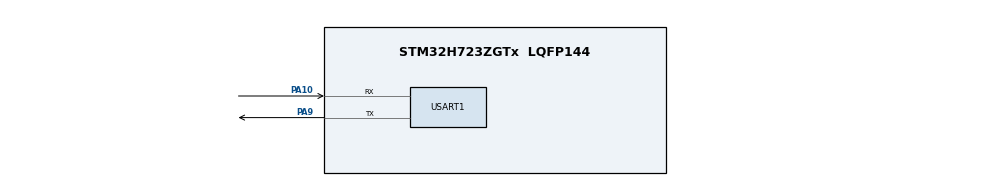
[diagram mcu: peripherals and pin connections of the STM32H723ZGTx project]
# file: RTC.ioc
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CORTEX_M7.default_mode_Activation=1
IWDG1.Prescaler=IWDG_PRESCALER_8
Mcu.Family=STM32H7
Mcu.Name=STM32H723ZGTx
Mcu.Package=LQFP144
NVIC.PriorityGroup=NVIC_PRIORITYGROUP_4
PA10.Mode=Asynchronous
PA10.Signal=USART1_RX
PA9.Mode=Asynchronous
PA9.Signal=USART1_TX
PC14-OSC32_IN.Mode=LSE-External-Oscillator
PC14-OSC32_IN.Signal=RCC_OSC32_IN
PC15-OSC32_OUT.Mode=LSE-External-Oscillator
PC15-OSC32_OUT.Signal=RCC_OSC32_OUT
PH0-OSC_IN.Mode=HSE-External-Oscillator
PH0-OSC_IN.Signal=RCC_OSC_IN
PH1-OSC_OUT.Mode=HSE-External-Oscillator
PH1-OSC_OUT.Signal=RCC_OSC_OUT
ProjectManager.HeapSize=0x200
ProjectManager.StackSize=0x400
ProjectManager.TargetToolchain=CMake
RCC.ADCFreq_Value=129000000
RCC.APB1Freq_Value=137500000
RCC.APB2Freq_Value=137500000
RCC.APB3Freq_Value=137500000
RCC.APB4Freq_Value=137500000
RCC.CortexFreq_Value=550000000
RCC.D1PPRE=RCC_APB3_DIV2
RCC.D2PPRE1=RCC_APB1_DIV2
RCC.D2PPRE2=RCC_APB2_DIV2
RCC.D3PPRE=RCC_APB4_DIV2
RCC.DIVM1=4
RCC.DIVN1=34
RCC.DIVP1=1
RCC.HCLKFreq_Value=275000000
RCC.HPRE=RCC_HCLK_DIV2
RCC.PLL2FRACN=0
RCC.PLL3FRACN=0
RCC.PLLFRACN=3072
RCC.SYSCLKFreq_VALUE=550000000
RCC.SYSCLKSource=RCC_SYSCLKSOURCE_PLLCLK
RCC.USBFreq_Value=275000000
USART1.VirtualMode-Asynchronous=VM_ASYNC
VP_IWDG1_VS_IWDG.Mode=IWDG_Activate
VP_MEMORYMAP_VS_MEMORYMAP.Mode=CurAppReg
VP_RTC_VS_RTC_Activate.Mode=RTC_Enabled
VP_RTC_VS_RTC_Calendar.Mode=RTC_Calendar
board=custom

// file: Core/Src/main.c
/* USER CODE BEGIN Header */
/**
  ******************************************************************************
  * @file           : main.c
  * @brief          : Main program body
  ******************************************************************************
  * @attention
  *
  * Copyright (c) 2026 STMicroelectronics.
  * All rights reserved.
  *
  * This software is licensed under terms that can be found in the LICENSE file
  * in the root directory of this software component.
  * If no LICENSE file comes with this software, it is provided AS-IS.
  *
  ******************************************************************************
  */
/* USER CODE END Header */
#include "main.h"
#include "iwdg.h"
#include "rtc.h"
#include "usart.h"
#include "gpio.h"

/* USER CODE BEGIN PTD */
typedef struct {
    RTC_TimeTypeDef SetTime; //设置时间
    RTC_DateTypeDef SetDate; //设置日期
    RTC_TimeTypeDef GetTime; //获取时间
    RTC_DateTypeDef GetDate; //获取日期
} RTC_DATA_T;

/* USER CODE END PTD */

/* USER CODE BEGIN PV */
RTC_DATA_T rtc_data = {0};
/* USER CODE END PV */

void SystemClock_Config(void);

static void MPU_Config(void);

/* USER CODE BEGIN 0 */
int _write(int file, char *ptr, int len) {
    HAL_UART_Transmit(&huart1, (uint8_t *) ptr, len, 1000);
    return len;
}

/* USER CODE END 0 */

int main(void) {

    /* MPU Configuration--------------------------------------------------------*/
    MPU_Config();

    /* MCU Configuration--------------------------------------------------------*/

    /* Reset of all peripherals, Initializes the Flash interface and the Systick. */
    HAL_Init();

    /* Configure the system clock */
    SystemClock_Config();

    /* Initialize all configured peripherals */
    MX_GPIO_Init();
    MX_IWDG1_Init();
    MX_RTC_Init();
    MX_USART1_UART_Init();
    printf("RTC demo start\r\n");
    if (HAL_RTCEx_BKUPRead(&hrtc,RTC_BKP_DR0) != 0x0202) {
        printf("first set RTC Init RTC \r\n");
        HAL_RTCEx_BKUPWrite(&hrtc,RTC_BKP_DR0, 0x0202);
        rtc_data.SetTime.Hours = 0;
        rtc_data.SetTime.Minutes = 0;
        rtc_data.SetTime.Seconds = 0;
        rtc_data.SetDate.Date = 2;
        rtc_data.SetDate.Month = 2;
        rtc_data.SetDate.Year = 97;
        HAL_RTC_SetTime(&hrtc, &rtc_data.SetTime,RTC_FORMAT_BIN);
        HAL_RTC_SetDate(&hrtc, &rtc_data.SetDate,RTC_FORMAT_BIN);
    }
    /* Infinite loop */
    /* USER CODE BEGIN WHILE */
    uint32_t start = 0;
    while (1) {
        start++;
        if (start % 80 == 0) {
            HAL_IWDG_Refresh(&hiwdg1);
        }
        if (start % 100 == 0) {
            HAL_RTC_GetTime(&hrtc, &rtc_data.GetTime,RTC_FORMAT_BIN);
            HAL_RTC_GetDate(&hrtc, &rtc_data.GetDate,RTC_FORMAT_BIN);
            printf("%02d-%02d-%02d %02d:%02d:%02d\r\n", rtc_data.GetDate.Year, rtc_data.GetDate.Month,
                   rtc_data.GetDate.Date,
                   rtc_data.GetTime.Hours, rtc_data.GetTime.Minutes, rtc_data.GetTime.Seconds);
        }
        HAL_Delay(10);
        /* USER CODE END WHILE */

    }
}

void SystemClock_Config(void) {
    RCC_OscInitTypeDef RCC_OscInitStruct = {0};
    RCC_ClkInitTypeDef RCC_ClkInitStruct = {0};

    /** Supply configuration update enable
    */
    HAL_PWREx_ConfigSupply(PWR_LDO_SUPPLY);

    /** Configure the main internal regulator output voltage
    */
    __HAL_PWR_VOLTAGESCALING_CONFIG(PWR_REGULATOR_VOLTAGE_SCALE0);

    while (!__HAL_PWR_GET_FLAG(PWR_FLAG_VOSRDY)) {
    }

    /** Initializes the RCC Oscillators according to the specified parameters
    * in the RCC_OscInitTypeDef structure.
    */
    RCC_OscInitStruct.OscillatorType = RCC_OSCILLATORTYPE_HSI | RCC_OSCILLATORTYPE_LSI;
    RCC_OscInitStruct.HSIState = RCC_HSI_DIV1;
    RCC_OscInitStruct.HSICalibrationValue = 64;
    RCC_OscInitStruct.LSIState = RCC_LSI_ON;
    RCC_OscInitStruct.PLL.PLLState = RCC_PLL_ON;
    RCC_OscInitStruct.PLL.PLLSource = RCC_PLLSOURCE_HSI;
    RCC_OscInitStruct.PLL.PLLM = 4;
    RCC_OscInitStruct.PLL.PLLN = 34;
    RCC_OscInitStruct.PLL.PLLP = 1;
    RCC_OscInitStruct.PLL.PLLQ = 2;
    RCC_OscInitStruct.PLL.PLLR = 2;
    RCC_OscInitStruct.PLL.PLLRGE = RCC_PLL1VCIRANGE_3;
    RCC_OscInitStruct.PLL.PLLVCOSEL = RCC_PLL1VCOWIDE;
    RCC_OscInitStruct.PLL.PLLFRACN = 3072;
    if (HAL_RCC_OscConfig(&RCC_OscInitStruct) != HAL_OK) {
        Error_Handler();
    }

    /** Initializes the CPU, AHB and APB buses clocks
    */
    RCC_ClkInitStruct.ClockType = RCC_CLOCKTYPE_HCLK | RCC_CLOCKTYPE_SYSCLK
                                  | RCC_CLOCKTYPE_PCLK1 | RCC_CLOCKTYPE_PCLK2
                                  | RCC_CLOCKTYPE_D3PCLK1 | RCC_CLOCKTYPE_D1PCLK1;
    RCC_ClkInitStruct.SYSCLKSource = RCC_SYSCLKSOURCE_PLLCLK;
    RCC_ClkInitStruct.SYSCLKDivider = RCC_SYSCLK_DIV1;
    RCC_ClkInitStruct.AHBCLKDivider = RCC_HCLK_DIV2;
    RCC_ClkInitStruct.APB3CLKDivider = RCC_APB3_DIV2;
    RCC_ClkInitStruct.APB1CLKDivider = RCC_APB1_DIV2;
    RCC_ClkInitStruct.APB2CLKDivider = RCC_APB2_DIV2;
    RCC_ClkInitStruct.APB4CLKDivider = RCC_APB4_DIV2;

    if (HAL_RCC_ClockConfig(&RCC_ClkInitStruct, FLASH_LATENCY_3) != HAL_OK) {
        Error_Handler();
    }
}

/* MPU Configuration */

void MPU_Config(void) {
    MPU_Region_InitTypeDef MPU_InitStruct = {0};

    /* Disables the MPU */
    HAL_MPU_Disable();

    /** Initializes and configures the Region and the memory to be protected
    */
    MPU_InitStruct.Enable = MPU_REGION_ENABLE;
    MPU_InitStruct.Number = MPU_REGION_NUMBER0;
    MPU_InitStruct.BaseAddress = 0x0;
    MPU_InitStruct.Size = MPU_REGION_SIZE_4GB;
    MPU_InitStruct.SubRegionDisable = 0x87;
    MPU_InitStruct.TypeExtField = MPU_TEX_LEVEL0;
    MPU_InitStruct.AccessPermission = MPU_REGION_NO_ACCESS;
    MPU_InitStruct.DisableExec = MPU_INSTRUCTION_ACCESS_DISABLE;
    MPU_InitStruct.IsShareable = MPU_ACCESS_SHAREABLE;
    MPU_InitStruct.IsCacheable = MPU_ACCESS_NOT_CACHEABLE;
    MPU_InitStruct.IsBufferable = MPU_ACCESS_NOT_BUFFERABLE;

    HAL_MPU_ConfigRegion(&MPU_InitStruct);
    /* Enables the MPU */
    HAL_MPU_Enable(MPU_PRIVILEGED_DEFAULT);
}

void Error_Handler(void) {
    __disable_irq();
    while (1) {
    }
}
